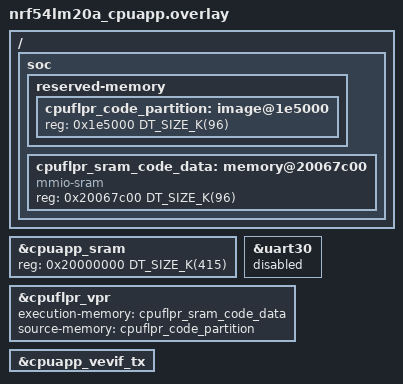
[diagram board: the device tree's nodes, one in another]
/*
 * Copyright (c) 2025 Nordic Semiconductor
 * SPDX-License-Identifier: Apache-2.0
 */

/ {
	soc {
		reserved-memory {
			#address-cells = <1>;
			#size-cells = <1>;

			cpuflpr_code_partition: image@1e5000 {
				/* FLPR core code partition */
				reg = <0x1e5000 DT_SIZE_K(96)>;
			};
		};

		cpuflpr_sram_code_data: memory@20067c00 {
			compatible = "mmio-sram";
			reg = <0x20067c00 DT_SIZE_K(96)>;
			#address-cells = <1>;
			#size-cells = <1>;
			ranges = <0x0 0x20067c00 DT_SIZE_K(96)>;
		};
	};
};

&cpuapp_sram {
	reg = <0x20000000 DT_SIZE_K(415)>;
	ranges = <0x0 0x20000000 DT_SIZE_K(415)>;
};

&uart30 {
	status = "reserved";
};

&cpuflpr_vpr {
	execution-memory = <&cpuflpr_sram_code_data>;
	source-memory = <&cpuflpr_code_partition>;
};

&cpuapp_vevif_tx {
	status = "okay";
};
